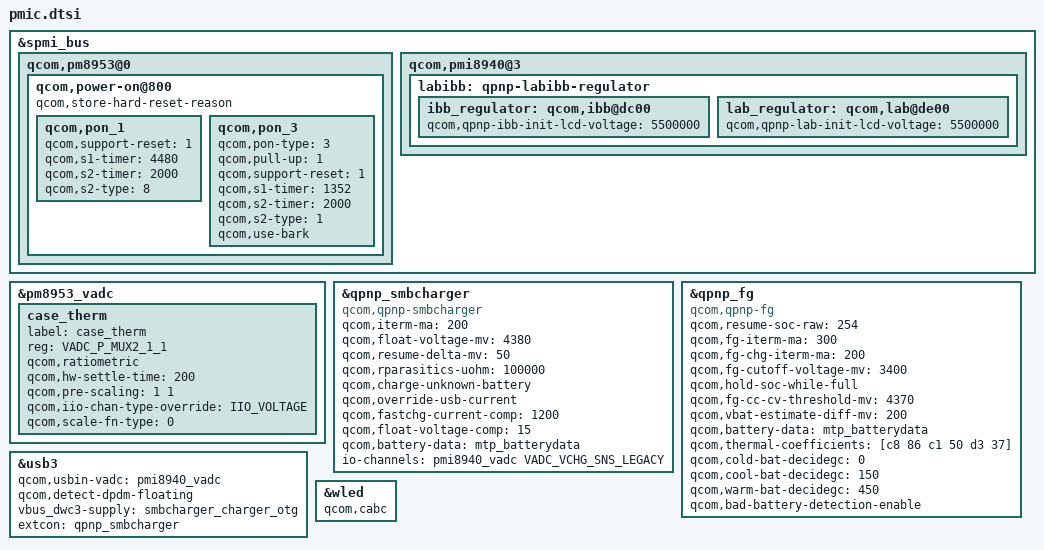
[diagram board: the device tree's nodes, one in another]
/* msm-pm8953 */
&spmi_bus {
	qcom,pm8953@0 {
		qcom,power-on@800 {
			qcom,store-hard-reset-reason;
			qcom,pon_1 {
				qcom,support-reset = <1>;
				qcom,s1-timer = <4480>;
				qcom,s2-timer = <2000>;
				qcom,s2-type = <8>;
			};

			qcom,pon_3 {
				qcom,pon-type = <3>;
				qcom,pull-up = <1>;
				qcom,support-reset = <1>;
				qcom,s1-timer = <1352>;
				qcom,s2-timer = <2000>;
				qcom,s2-type = <1>;
				qcom,use-bark;
			};
		};
		/delete-node/ qcom,pm8953_typec@bf00;
	};
};

&pm8953_vadc {
	/delete-node/ chan@13;
};

&pm8953_vadc {
	case_therm {
		label = "case_therm";
		reg = <VADC_P_MUX2_1_1>;
		qcom,ratiometric;
		qcom,hw-settle-time = <200>;
		qcom,pre-scaling = <1 1>;

		qcom,iio-chan-type-override = "IIO_VOLTAGE";
		qcom,scale-fn-type = <0>; // SCALE_DEFAULT
	};
};	

/* msm-pmi8940 */
&qpnp_smbcharger {
	compatible = "qcom,qpnp-smbcharger";

	qcom,iterm-ma = <200>;
	qcom,float-voltage-mv = <4380>;
	qcom,resume-delta-mv = <50>;
	/delete-property/ qcom,rparasitic-uohm;
	qcom,rparasitics-uohm = <100000>;
	qcom,charge-unknown-battery;
	/delete-property/ qcom,parallel-usb-min-current-ma;
	/delete-property/ qcom,parallel-usb-9v-min-current-ma;
	/delete-property/ qcom,parallel-allowed-lowering-ma;
	qcom,override-usb-current;
	qcom,fastchg-current-comp = <1200>;
	qcom,float-voltage-comp = <15>;
	/delete-property/ qcom,autoadjust-vfloat;
	qcom,battery-data = <&mtp_batterydata>;
	/delete-property/ qcom,external-typec;
	/delete-property/ qcom,typec-psy-name;
	io-channels = <&pmi8940_vadc VADC_VCHG_SNS_LEGACY>;
	io-channel-names = "vchg_sns";
	status = "okay";
};

&qpnp_fg {
	compatible = "qcom,qpnp-fg";

	/delete-property/ qcom,resume-soc;
	qcom,resume-soc-raw = <254>;
	qcom,fg-iterm-ma = <300>;
	qcom,fg-chg-iterm-ma = <200>;
	qcom,fg-cutoff-voltage-mv = <3400>;
	qcom,hold-soc-while-full;
	qcom,fg-cc-cv-threshold-mv =<4370>;
	qcom,vbat-estimate-diff-mv = <200>;
	qcom,battery-data = <&mtp_batterydata>;
	qcom,thermal-coefficients = [c8 86 c1 50 d3 37];
	qcom,cold-bat-decidegc = <0>;
	qcom,cool-bat-decidegc = <150>;
	qcom,warm-bat-decidegc = <450>;
	qcom,bad-battery-detection-enable;
	status = "okay";
};

&usb3 {
	qcom,usbin-vadc = <&pmi8940_vadc>;
	qcom,detect-dpdm-floating;
	vbus_dwc3-supply = <&smbcharger_charger_otg>;
	extcon = <&qpnp_smbcharger>;
};

&spmi_bus {
	qcom,pmi8940@3 {
		labibb: qpnp-labibb-regulator {
			status = "ok";
			ibb_regulator: qcom,ibb@dc00 {
				qcom,qpnp-ibb-init-lcd-voltage = <5500000>;
			};

			lab_regulator: qcom,lab@de00 {
				qcom,qpnp-lab-init-lcd-voltage = <5500000>;
			};
		};
	};
};

&wled {
	qcom,cabc;
};
